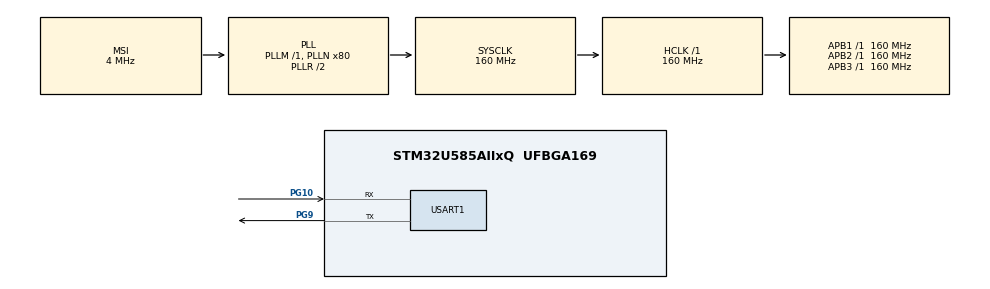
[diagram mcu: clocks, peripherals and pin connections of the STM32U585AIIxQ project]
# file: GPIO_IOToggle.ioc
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CORTEX_M33_NS.userName=CORTEX_M33
Mcu.Family=STM32U5
Mcu.Name=STM32U585AIIxQ
Mcu.Package=UFBGA169
NVIC.PriorityGroup=NVIC_PRIORITYGROUP_4
PG10.Mode=Asynchronous
PG10.Signal=USART1_RX
PG9.Mode=Asynchronous
PG9.Signal=USART1_TX
PWR.PowerMode=PWR_SMPS_SUPPLY
ProjectManager.HeapSize=0x200
ProjectManager.StackSize=0x400
ProjectManager.TargetToolchain=CMake
RCC.ADCFreq_Value=16000000
RCC.AHBFreq_Value=160000000
RCC.APB1Freq_Value=160000000
RCC.APB1TimFreq_Value=160000000
RCC.APB2Freq_Value=160000000
RCC.APB2TimFreq_Value=160000000
RCC.APB3Freq_Value=160000000
RCC.CortexFreq_Value=160000000
RCC.DACCLockSelectionVirtual=RCC_DAC1CLKSOURCE_LSI
RCC.EPOD_VALUE=4000000
RCC.HCLKFreq_Value=160000000
RCC.HSE_VALUE=16000000
RCC.HSI48_VALUE=48000000
RCC.HSI_VALUE=16000000
RCC.LSE_VALUE=32768
RCC.LSIDIV_VALUE=32000
RCC.MSI_VALUE=4000000
RCC.PLLN=80
RCC.SYSCLKFreq_VALUE=160000000
RCC.SYSCLKSource=RCC_SYSCLKSOURCE_PLLCLK
RCC.USBFreq_Value=48000000
RCC.VCOOutputFreq_Value=320000000
USART1.VirtualMode-Asynchronous=VM_ASYNC
VP_ICACHE_VS_ICACHE.Mode=DirectMappedCache
VP_LPBAMQUEUE_VS_QUEUE.Mode=QUEUEMODE
VP_LPBAM_VS_SIG1.Mode=SmartRun
VP_LPBAM_VS_SIG4.Mode=LPDMA1
VP_MEMORYMAP_VS_MEMORYMAP.Mode=CurAppReg
VP_PWR_VS_DBSignals.Mode=DisableDeadBatterySignals
VP_PWR_VS_LPOM.Mode=PowerOptimisation
VP_PWR_VS_SECSignals.Mode=Security/Privilege
board=B-U585I-IOT02A

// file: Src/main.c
/* USER CODE BEGIN Header */
/**
  ******************************************************************************
  * @file    GPIO/GPIO_IOToggle/Src/main.c
  * @author  MCD Application Team
  * @brief   Configure and toggle an on-board LED through the STM32U5xx HAL API.
  ******************************************************************************
  * @attention
  *
  * Copyright (c) 2021 STMicroelectronics.
  * All rights reserved.
  *
  * This software is licensed under terms that can be found in the LICENSE file
  * in the root directory of this software component.
  * If no LICENSE file comes with this software, it is provided AS-IS.
  *
  ******************************************************************************
  */
/* USER CODE END Header */

#include "main.h"
#include <stdio.h>
#include <string.h>

/* USER CODE BEGIN PV */
static GPIO_InitTypeDef GPIO_InitStruct;
static UART_HandleTypeDef huart1;

static uint8_t rx_byte;
static volatile uint8_t cmd_ready = 0;
static volatile uint8_t cmd = 0;
static volatile uint32_t counter = 0;
/* USER CODE END PV */

void SystemClock_Config(void);
static void SystemPower_Config(void);
static void MX_ICACHE_Init(void);
/* USER CODE BEGIN PFP */
static void MX_LED_GPIO_Init(void);
static void MX_USART1_UART_Init(void);
/* USER CODE END PFP */

/* USER CODE BEGIN 0 */
static void uart_print(const char *s) {
    HAL_UART_Transmit(&huart1, (uint8_t *)s, strlen(s), HAL_MAX_DELAY);
}

static void print_help(void) {
    uart_print("\r\nLab2 Task1: interrupt UART CLI\r\n");
    uart_print("h: print help\r\n");
    uart_print("c: print counter\r\n");
}

void HAL_UART_RxCpltCallback(UART_HandleTypeDef *huart) {
    if (huart == &huart1) {
        cmd = rx_byte;
        cmd_ready = 1;

        HAL_UART_Receive_IT(&huart1, &rx_byte, 1);
    }
}
/* USER CODE END 0 */

int main(void) {
  /* MCU Configuration--------------------------------------------------------*/

  /* Reset of all peripherals, initializes the Flash interface and the Systick. */
  HAL_Init();

  /* Configure the system clock. */
  SystemClock_Config();

  /* Configure the system power. */
  SystemPower_Config();

  /* Initialize all configured peripherals. */
  MX_ICACHE_Init();

  /* USER CODE BEGIN 2 */
  MX_LED_GPIO_Init();
  MX_USART1_UART_Init();

  print_help();

  if (HAL_UART_Receive_IT(&huart1, &rx_byte, 1) != HAL_OK) {
    uart_print("HAL_UART_Receive_IT failed\r\n");
  }
  /* USER CODE END 2 */

  /* Infinite loop */
  while (1) {

    /* USER CODE BEGIN 3 */
    counter++;

    if (cmd_ready) {
        uint8_t local_cmd = cmd;
        cmd_ready = 0;

        switch (local_cmd) {
        case 'h':
            print_help();
            break;

        case 'c': {
            char msg[64];
            snprintf(msg, sizeof(msg), "\r\ncounter = %lu\r\n", counter);
            uart_print(msg);
            break;
        }

        case '\r':
        case '\n':
            break;

        default:
            uart_print("\r\nUnknown command\r\n");
            break;
        }
    }
    /* USER CODE END 3 */
  }
  /* USER CODE END WHILE */
}

/* USER CODE BEGIN 4 */

/**
  * @brief USART1 interrupt handler.
  * @retval None
  */
void USART1_IRQHandler(void) {
  HAL_UART_IRQHandler(&huart1);
}

/**
  * @brief  Configure the on-board LED GPIOs using the STM32 HAL API.
  * @note   LED7 is the green user LED on the B-U585I-IOT02A board.
  *         The BSP maps LED7 to GPIOH pin 7.
  * @retval None
  */
static void MX_LED_GPIO_Init(void) {
  /* Enable GPIO clocks for the on-board LEDs. */
  LED7_GPIO_CLK_ENABLE();
  LED6_GPIO_CLK_ENABLE();

  /* Configure the LED pins as output push-pull. */
  GPIO_InitStruct.Mode  = GPIO_MODE_OUTPUT_PP;
  GPIO_InitStruct.Pull  = GPIO_NOPULL;
  GPIO_InitStruct.Speed = GPIO_SPEED_FREQ_HIGH;

  GPIO_InitStruct.Pin = LED7_PIN;
  HAL_GPIO_Init(LED7_GPIO_PORT, &GPIO_InitStruct);

  GPIO_InitStruct.Pin = LED6_PIN;
  HAL_GPIO_Init(LED6_GPIO_PORT, &GPIO_InitStruct);

  /* Start from a known state. */
  HAL_GPIO_WritePin(LED7_GPIO_PORT, LED7_PIN, GPIO_PIN_SET);
  HAL_GPIO_WritePin(LED6_GPIO_PORT, LED6_PIN, GPIO_PIN_SET);
}

/**
  * @brief USART1 Initialization Function
  * @param None
  * @retval None
  */
static void MX_USART1_UART_Init(void) {
  huart1.Instance = USART1;
  huart1.Init.BaudRate = 115200;
  huart1.Init.WordLength = UART_WORDLENGTH_8B;
  huart1.Init.StopBits = UART_STOPBITS_1;
  huart1.Init.Parity = UART_PARITY_NONE;
  huart1.Init.Mode = UART_MODE_TX_RX;
  huart1.Init.HwFlowCtl = UART_HWCONTROL_NONE;
  huart1.Init.OverSampling = UART_OVERSAMPLING_16;
  huart1.Init.OneBitSampling = UART_ONE_BIT_SAMPLE_DISABLE;
  huart1.Init.ClockPrescaler = UART_PRESCALER_DIV1;
  huart1.AdvancedInit.AdvFeatureInit = UART_ADVFEATURE_NO_INIT;

  if (HAL_UART_Init(&huart1) != HAL_OK) {
    Error_Handler();
  }

  if (HAL_UARTEx_SetTxFifoThreshold(&huart1, UART_TXFIFO_THRESHOLD_1_8) != HAL_OK) {
    Error_Handler();
  }

  if (HAL_UARTEx_SetRxFifoThreshold(&huart1, UART_RXFIFO_THRESHOLD_1_8) != HAL_OK) {
    Error_Handler();
  }

  if (HAL_UARTEx_DisableFifoMode(&huart1) != HAL_OK) {
    Error_Handler();
  }

  HAL_NVIC_SetPriority(USART1_IRQn, 0, 0);
  HAL_NVIC_EnableIRQ(USART1_IRQn);
}

/* USER CODE END 4 */

void SystemClock_Config(void) {
  RCC_OscInitTypeDef RCC_OscInitStruct = {0};
  RCC_ClkInitTypeDef RCC_ClkInitStruct = {0};

  /** Configure the main internal regulator output voltage. */
  if (HAL_PWREx_ControlVoltageScaling(PWR_REGULATOR_VOLTAGE_SCALE1) != HAL_OK) {
    Error_Handler();
  }

  /** Initializes the CPU, AHB and APB buses clocks. */
  RCC_OscInitStruct.OscillatorType = RCC_OSCILLATORTYPE_MSI;
  RCC_OscInitStruct.MSIState = RCC_MSI_ON;
  RCC_OscInitStruct.MSICalibrationValue = RCC_MSICALIBRATION_DEFAULT;
  RCC_OscInitStruct.MSIClockRange = RCC_MSIRANGE_4;
  RCC_OscInitStruct.PLL.PLLState = RCC_PLL_ON;
  RCC_OscInitStruct.PLL.PLLSource = RCC_PLLSOURCE_MSI;
  RCC_OscInitStruct.PLL.PLLMBOOST = RCC_PLLMBOOST_DIV1;
  RCC_OscInitStruct.PLL.PLLM = 1;
  RCC_OscInitStruct.PLL.PLLN = 80;
  RCC_OscInitStruct.PLL.PLLP = 2;
  RCC_OscInitStruct.PLL.PLLQ = 2;
  RCC_OscInitStruct.PLL.PLLR = 2;
  RCC_OscInitStruct.PLL.PLLRGE = RCC_PLLVCIRANGE_0;
  RCC_OscInitStruct.PLL.PLLFRACN = 0;

  if (HAL_RCC_OscConfig(&RCC_OscInitStruct) != HAL_OK) {
    Error_Handler();
  }

  /** Initializes the CPU, AHB and APB buses clocks. */
  RCC_ClkInitStruct.ClockType = RCC_CLOCKTYPE_HCLK | RCC_CLOCKTYPE_SYSCLK
                              | RCC_CLOCKTYPE_PCLK1 | RCC_CLOCKTYPE_PCLK2
                              | RCC_CLOCKTYPE_PCLK3;
  RCC_ClkInitStruct.SYSCLKSource = RCC_SYSCLKSOURCE_PLLCLK;
  RCC_ClkInitStruct.AHBCLKDivider = RCC_SYSCLK_DIV1;
  RCC_ClkInitStruct.APB1CLKDivider = RCC_HCLK_DIV1;
  RCC_ClkInitStruct.APB2CLKDivider = RCC_HCLK_DIV1;
  RCC_ClkInitStruct.APB3CLKDivider = RCC_HCLK_DIV1;

  if (HAL_RCC_ClockConfig(&RCC_ClkInitStruct, FLASH_LATENCY_4) != HAL_OK) {
    Error_Handler();
  }
}

/**
  * @brief Power Configuration
  * @retval None
  */
static void SystemPower_Config(void) {
  /*
   * Disable the internal pull-up in dead battery pins of UCPD peripheral.
   */
  HAL_PWREx_DisableUCPDDeadBattery();

  /*
   * Switch to SMPS regulator instead of LDO.
   */
  if (HAL_PWREx_ConfigSupply(PWR_SMPS_SUPPLY) != HAL_OK) {
    Error_Handler();
  }

}

static void MX_ICACHE_Init(void) {

  /** Enable instruction cache in 1-way direct mapped cache mode. */
  if (HAL_ICACHE_ConfigAssociativityMode(ICACHE_1WAY) != HAL_OK) {
    Error_Handler();
  }

  if (HAL_ICACHE_Enable() != HAL_OK) {
    Error_Handler();
  }

}

void Error_Handler(void) {
  while (1) {
  }
}
